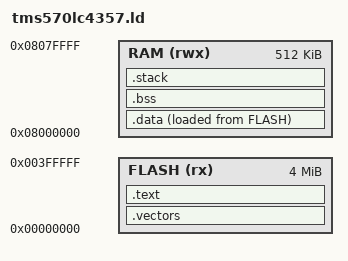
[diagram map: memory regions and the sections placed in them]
ENTRY(_reset)

MEMORY
{
    FLASH (rx)  : ORIGIN = 0x00000000, LENGTH = 4096K
    RAM   (rwx) : ORIGIN = 0x08000000, LENGTH = 512K
}

_stack_size = 0x4000; /* 16 KB Stack */

SECTIONS
{
    .vectors :
    {
        KEEP(*(.vectors))
    } > FLASH

    .text :
    {
        *(.text*)
        *(.rodata*)
        . = ALIGN(4);
    } > FLASH

    _sidata = LOADADDR(.data);

    .data :
    {
        . = ALIGN(4);
        _sdata = .;
        *(.data*)
        . = ALIGN(4);
        _edata = .;
    } > RAM AT > FLASH

    .bss :
    {
        . = ALIGN(4);
        __bss_start__ = .;
        *(.bss*)
        *(COMMON)
        . = ALIGN(4);
        __bss_end__ = .;
    } > RAM

    .stack (NOLOAD) :
    {
        . = ALIGN(8);
        . = . + _stack_size;
        _stack_top = .;
    } > RAM
}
